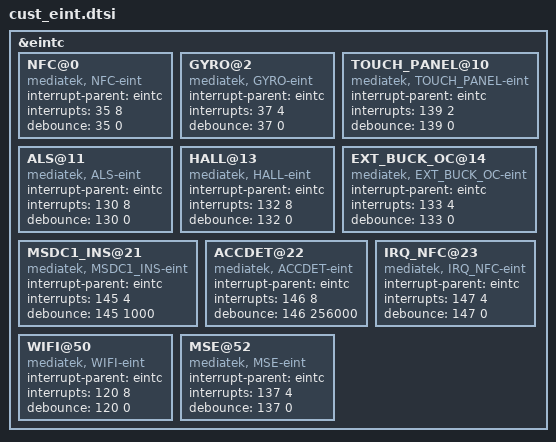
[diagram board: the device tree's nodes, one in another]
/*
 * Generated by MTK SP DrvGen Version 03.13.6 for MT6752. Copyright MediaTek Inc. (C) 2013.
 * Fri Jul 03 20:28:27 2015
 * Do Not Modify the File.
 */

/*************************
 * EINT DTSI File
*************************/

&eintc {
	NFC@0 {
		compatible = "mediatek, NFC-eint";
		interrupt-parent = <&eintc>;
		interrupts = <35 8>;
		debounce = <35 0>;
	};

	GYRO@2 {
		compatible = "mediatek, GYRO-eint";
		interrupt-parent = <&eintc>;
		interrupts = <37 4>;
		debounce = <37 0>;
	};

	TOUCH_PANEL@10 {
		compatible = "mediatek, TOUCH_PANEL-eint";
		interrupt-parent = <&eintc>;
		interrupts = <139 2>;
		debounce = <139 0>;
	};

	ALS@11 {
		compatible = "mediatek, ALS-eint";
		interrupt-parent = <&eintc>;
		interrupts = <130 8>;
		debounce = <130 0>;
	};

	HALL@13 {
		compatible = "mediatek, HALL-eint";
		interrupt-parent = <&eintc>;
		interrupts = <132 8>;
		debounce = <132 0>;
	};

	EXT_BUCK_OC@14 {
		compatible = "mediatek, EXT_BUCK_OC-eint";
		interrupt-parent = <&eintc>;
		interrupts = <133 4>;
		debounce = <133 0>;
	};

	MSDC1_INS@21 {
		compatible = "mediatek, MSDC1_INS-eint";
		interrupt-parent = <&eintc>;
		interrupts = <145 4>;
		debounce = <145 1000>;
	};

	ACCDET@22 {
		compatible = "mediatek, ACCDET-eint";
		interrupt-parent = <&eintc>;
		interrupts = <146 8>;
		debounce = <146 256000>;
	};

	IRQ_NFC@23 {
		compatible = "mediatek, IRQ_NFC-eint";
		interrupt-parent = <&eintc>;
		interrupts = <147 4>;
		debounce = <147 0>;
	};

	WIFI@50 {
		compatible = "mediatek, WIFI-eint";
		interrupt-parent = <&eintc>;
		interrupts = <120 8>;
		debounce = <120 0>;
	};

	MSE@52 {
		compatible = "mediatek, MSE-eint";
		interrupt-parent = <&eintc>;
		interrupts = <137 4>;
		debounce = <137 0>;
	};

};
